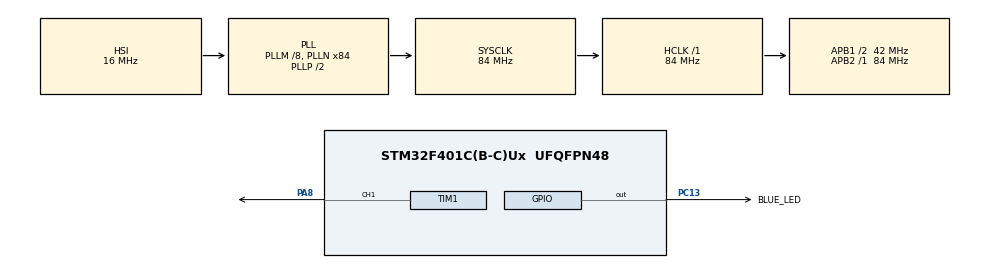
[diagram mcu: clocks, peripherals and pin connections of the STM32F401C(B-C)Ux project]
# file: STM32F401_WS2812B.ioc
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Dma.Request0=TIM1_CH1
Dma.TIM1_CH1.0.Direction=DMA_MEMORY_TO_PERIPH
Dma.TIM1_CH1.0.FIFOMode=DMA_FIFOMODE_ENABLE
Dma.TIM1_CH1.0.FIFOThreshold=DMA_FIFO_THRESHOLD_FULL
Dma.TIM1_CH1.0.Instance=DMA2_Stream1
Dma.TIM1_CH1.0.MemBurst=DMA_MBURST_SINGLE
Dma.TIM1_CH1.0.MemDataAlignment=DMA_MDATAALIGN_WORD
Dma.TIM1_CH1.0.MemInc=DMA_MINC_ENABLE
Dma.TIM1_CH1.0.Mode=DMA_CIRCULAR
Dma.TIM1_CH1.0.PeriphBurst=DMA_PBURST_SINGLE
Dma.TIM1_CH1.0.PeriphDataAlignment=DMA_PDATAALIGN_WORD
Dma.TIM1_CH1.0.PeriphInc=DMA_PINC_DISABLE
Dma.TIM1_CH1.0.Priority=DMA_PRIORITY_VERY_HIGH
Mcu.Family=STM32F4
Mcu.Name=STM32F401C(B-C)Ux
Mcu.Package=UFQFPN48
NVIC.DMA2_Stream1_IRQn=true\:0\:0\:false\:false\:true\:false\:true\:true
NVIC.PriorityGroup=NVIC_PRIORITYGROUP_4
PA8.Signal=S_TIM1_CH1
PC13-ANTI_TAMP.GPIO_Label=BLUE_LED
PC13-ANTI_TAMP.Signal=GPIO_Output
PH0\ -\ OSC_IN.Mode=HSE-External-Oscillator
PH0\ -\ OSC_IN.Signal=RCC_OSC_IN
PH1\ -\ OSC_OUT.Mode=HSE-External-Oscillator
PH1\ -\ OSC_OUT.Signal=RCC_OSC_OUT
ProjectManager.HeapSize=0x200
ProjectManager.StackSize=0x400
ProjectManager.TargetToolchain=Makefile
RCC.48MHZClocksFreq_Value=42000000
RCC.AHBFreq_Value=84000000
RCC.APB1CLKDivider=RCC_HCLK_DIV2
RCC.APB1Freq_Value=42000000
RCC.APB1TimFreq_Value=84000000
RCC.APB2Freq_Value=84000000
RCC.APB2TimFreq_Value=84000000
RCC.CortexFreq_Value=84000000
RCC.HCLKFreq_Value=84000000
RCC.HSE_VALUE=25000000
RCC.HSI_VALUE=16000000
RCC.LSE_VALUE=32768
RCC.PLLM=8
RCC.PLLN=84
RCC.SYSCLKFreq_VALUE=84000000
RCC.SYSCLKSource=RCC_SYSCLKSOURCE_PLLCLK
RCC.VCOOutputFreq_Value=168000000
SH.S_TIM1_CH1.0=TIM1_CH1,PWM Generation1 CH1
TIM1.AutoReloadPreload=TIM_AUTORELOAD_PRELOAD_ENABLE
TIM1.BreakPolarity=TIM_BREAKPOLARITY_LOW
TIM1.Channel-PWM\ Generation1\ CH1=TIM_CHANNEL_1
TIM1.CounterMode=TIM_COUNTERMODE_UP
TIM1.OC1Preload_PWM=ENABLE
TIM1.OCFastMode_PWM-PWM\ Generation1\ CH1=TIM_OCFAST_DISABLE
TIM1.OCPolarity_1=TIM_OCPOLARITY_HIGH
TIM1.Period=90
VP_TIM1_VS_ClockSourceINT.Mode=Internal
board=custom

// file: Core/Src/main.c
/* USER CODE BEGIN Header */
/**
  ******************************************************************************
  * @file           : main.c
  * @brief          : Main program body
  ******************************************************************************
  * @attention
  *
  * Copyright (c) 2026 STMicroelectronics.
  * All rights reserved.
  *
  * This software is licensed under terms that can be found in the LICENSE file
  * in the root directory of this software component.
  * If no LICENSE file comes with this software, it is provided AS-IS.
  *
  ******************************************************************************
  */
/* USER CODE END Header */
#include "main.h"

/* USER CODE BEGIN Includes */

#include <math.h>
#include "WS2812B.h"

/* USER CODE END Includes */

TIM_HandleTypeDef htim1;
DMA_HandleTypeDef hdma_tim1_ch1;

void SystemClock_Config(void);
static void MX_GPIO_Init(void);
static void MX_DMA_Init(void);
static void MX_TIM1_Init(void);

int main(void)
{

  /* MCU Configuration--------------------------------------------------------*/

  /* Reset of all peripherals, Initializes the Flash interface and the Systick. */
  HAL_Init();

  /* Configure the system clock */
  SystemClock_Config();

  /* Initialize all configured peripherals */
  MX_GPIO_Init();
  MX_DMA_Init();
  MX_TIM1_Init();
  /* USER CODE BEGIN 2 */

    uint8_t angle = 0;
    const uint8_t angle_difference = 11;

  /* USER CODE END 2 */

  /* Infinite loop */
  /* USER CODE BEGIN WHILE */
    while (1)
    {
        for (uint8_t i = 0; i < 12; i++) {
            // Calculate color
            uint32_t rgb_color = hsl_to_rgb(angle + (i * angle_difference), 255, 3);
            // Set color
            led_set_RGB(i, (rgb_color >> 16) & 0xFF, (rgb_color >> 8) & 0xFF, rgb_color & 0xFF);
            //led_set_RGB(i, 21, 61, 14);
        }
        // Write to LED
        ++angle;
        led_render();
        // Some delay
        HAL_Delay(10);

    /* USER CODE END WHILE */

    }
}

void SystemClock_Config(void)
{
  RCC_OscInitTypeDef RCC_OscInitStruct = {0};
  RCC_ClkInitTypeDef RCC_ClkInitStruct = {0};

  /** Configure the main internal regulator output voltage
  */
  __HAL_RCC_PWR_CLK_ENABLE();
  __HAL_PWR_VOLTAGESCALING_CONFIG(PWR_REGULATOR_VOLTAGE_SCALE2);

  /** Initializes the RCC Oscillators according to the specified parameters
  * in the RCC_OscInitTypeDef structure.
  */
  RCC_OscInitStruct.OscillatorType = RCC_OSCILLATORTYPE_HSI;
  RCC_OscInitStruct.HSIState = RCC_HSI_ON;
  RCC_OscInitStruct.HSICalibrationValue = RCC_HSICALIBRATION_DEFAULT;
  RCC_OscInitStruct.PLL.PLLState = RCC_PLL_ON;
  RCC_OscInitStruct.PLL.PLLSource = RCC_PLLSOURCE_HSI;
  RCC_OscInitStruct.PLL.PLLM = 8;
  RCC_OscInitStruct.PLL.PLLN = 84;
  RCC_OscInitStruct.PLL.PLLP = RCC_PLLP_DIV2;
  RCC_OscInitStruct.PLL.PLLQ = 4;
  if (HAL_RCC_OscConfig(&RCC_OscInitStruct) != HAL_OK)
  {
    Error_Handler();
  }

  /** Initializes the CPU, AHB and APB buses clocks
  */
  RCC_ClkInitStruct.ClockType = RCC_CLOCKTYPE_HCLK|RCC_CLOCKTYPE_SYSCLK
                              |RCC_CLOCKTYPE_PCLK1|RCC_CLOCKTYPE_PCLK2;
  RCC_ClkInitStruct.SYSCLKSource = RCC_SYSCLKSOURCE_PLLCLK;
  RCC_ClkInitStruct.AHBCLKDivider = RCC_SYSCLK_DIV1;
  RCC_ClkInitStruct.APB1CLKDivider = RCC_HCLK_DIV2;
  RCC_ClkInitStruct.APB2CLKDivider = RCC_HCLK_DIV1;

  if (HAL_RCC_ClockConfig(&RCC_ClkInitStruct, FLASH_LATENCY_2) != HAL_OK)
  {
    Error_Handler();
  }
}

static void MX_TIM1_Init(void)
{

  TIM_ClockConfigTypeDef sClockSourceConfig = {0};
  TIM_MasterConfigTypeDef sMasterConfig = {0};
  TIM_OC_InitTypeDef sConfigOC = {0};
  TIM_BreakDeadTimeConfigTypeDef sBreakDeadTimeConfig = {0};

  htim1.Instance = TIM1;
  htim1.Init.Prescaler = 0;
  htim1.Init.CounterMode = TIM_COUNTERMODE_UP;
  htim1.Init.Period = 90;
  htim1.Init.ClockDivision = TIM_CLOCKDIVISION_DIV1;
  htim1.Init.RepetitionCounter = 0;
  htim1.Init.AutoReloadPreload = TIM_AUTORELOAD_PRELOAD_ENABLE;
  if (HAL_TIM_Base_Init(&htim1) != HAL_OK)
  {
    Error_Handler();
  }
  sClockSourceConfig.ClockSource = TIM_CLOCKSOURCE_INTERNAL;
  if (HAL_TIM_ConfigClockSource(&htim1, &sClockSourceConfig) != HAL_OK)
  {
    Error_Handler();
  }
  if (HAL_TIM_PWM_Init(&htim1) != HAL_OK)
  {
    Error_Handler();
  }
  sMasterConfig.MasterOutputTrigger = TIM_TRGO_RESET;
  sMasterConfig.MasterSlaveMode = TIM_MASTERSLAVEMODE_DISABLE;
  if (HAL_TIMEx_MasterConfigSynchronization(&htim1, &sMasterConfig) != HAL_OK)
  {
    Error_Handler();
  }
  sConfigOC.OCMode = TIM_OCMODE_PWM1;
  sConfigOC.Pulse = 0;
  sConfigOC.OCPolarity = TIM_OCPOLARITY_HIGH;
  sConfigOC.OCNPolarity = TIM_OCNPOLARITY_HIGH;
  sConfigOC.OCFastMode = TIM_OCFAST_DISABLE;
  sConfigOC.OCIdleState = TIM_OCIDLESTATE_RESET;
  sConfigOC.OCNIdleState = TIM_OCNIDLESTATE_RESET;
  if (HAL_TIM_PWM_ConfigChannel(&htim1, &sConfigOC, TIM_CHANNEL_1) != HAL_OK)
  {
    Error_Handler();
  }
  sBreakDeadTimeConfig.OffStateRunMode = TIM_OSSR_DISABLE;
  sBreakDeadTimeConfig.OffStateIDLEMode = TIM_OSSI_DISABLE;
  sBreakDeadTimeConfig.LockLevel = TIM_LOCKLEVEL_OFF;
  sBreakDeadTimeConfig.DeadTime = 0;
  sBreakDeadTimeConfig.BreakState = TIM_BREAK_DISABLE;
  sBreakDeadTimeConfig.BreakPolarity = TIM_BREAKPOLARITY_LOW;
  sBreakDeadTimeConfig.AutomaticOutput = TIM_AUTOMATICOUTPUT_DISABLE;
  if (HAL_TIMEx_ConfigBreakDeadTime(&htim1, &sBreakDeadTimeConfig) != HAL_OK)
  {
    Error_Handler();
  }
  HAL_TIM_MspPostInit(&htim1);

}

static void MX_DMA_Init(void)
{

  /* DMA controller clock enable */
  __HAL_RCC_DMA2_CLK_ENABLE();

  /* DMA interrupt init */
  /* DMA2_Stream1_IRQn interrupt configuration */
  HAL_NVIC_SetPriority(DMA2_Stream1_IRQn, 0, 0);
  HAL_NVIC_EnableIRQ(DMA2_Stream1_IRQn);

}

static void MX_GPIO_Init(void)
{
  GPIO_InitTypeDef GPIO_InitStruct = {0};

  /* GPIO Ports Clock Enable */
  __HAL_RCC_GPIOC_CLK_ENABLE();
  __HAL_RCC_GPIOH_CLK_ENABLE();
  __HAL_RCC_GPIOA_CLK_ENABLE();

  /*Configure GPIO pin Output Level */
  HAL_GPIO_WritePin(BLUE_LED_GPIO_Port, BLUE_LED_Pin, GPIO_PIN_RESET);

  /*Configure GPIO pin : BLUE_LED_Pin */
  GPIO_InitStruct.Pin = BLUE_LED_Pin;
  GPIO_InitStruct.Mode = GPIO_MODE_OUTPUT_PP;
  GPIO_InitStruct.Pull = GPIO_NOPULL;
  GPIO_InitStruct.Speed = GPIO_SPEED_FREQ_LOW;
  HAL_GPIO_Init(BLUE_LED_GPIO_Port, &GPIO_InitStruct);

}

void Error_Handler(void)
{
    __disable_irq();
    while (1)
    {
    }
}
